# MCU_FSS0_OSPI_0_OSPI0_SS_CFG register map
Vendor: Texas Instruments
Peripheral module from a debugger description file (folder J7_AHP).
Registers are 32-bit, read-only, reset 0x0 unless marked. A register's access mark holds for its fields unless they carry their own. Offsets are as the file gives them; lines under a group give offsets from that group; [hi:lo] are bit positions; {n}, {i} and the like mark numbered series; 'fields as' and 'values as' point back to an identical list; <NAME> marks a mode.

## MCU_FSS0_OSPI_0_OSPI0_SS_CFG
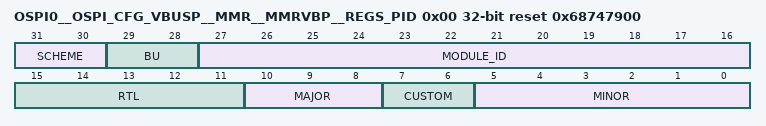
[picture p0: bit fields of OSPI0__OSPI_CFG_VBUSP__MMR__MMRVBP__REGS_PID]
0x00 OSPI0__OSPI_CFG_VBUSP__MMR__MMRVBP__REGS_PID reset 0x68747900
  [31:30] SCHEME — PID register scheme
  [29:28] BU — Business Unit: 10 = Processors
  [27:16] MODULE_ID
  [15:11] RTL — RTL revision. Will vary depending on release.
  [10:8] MAJOR — Major revision
  [7:6] CUSTOM
  [5:0] MINOR — Minor revision
0x04 OSPI0__OSPI_CFG_VBUSP__MMR__MMRVBP__REGS_CTRL rw
  [3] PIPELINE_MODE_FLUSH — 1 - Flush Cadence Flash Controller FIFO by forcin gAHB SEL low. 0 - AHB Sel to Cadence Controller is 1
0x08 OSPI0__OSPI_CFG_VBUSP__MMR__MMRVBP__REGS_STAT
  [1] MEM_INIT_DONE — 0:Memory Initialization is in progress, 1:Memory Intialization Done
0x20 OSPI0__OSPI_CFG_VBUSP__MMR__MMRVBP__REGS_EOI wo
  [7:0] EOI — Write with bit position of targetted interrupt. (E.g. Ext TS is bit 0). Upon write, level interrupt will clear and if unserviced interrupt counter > 1 will issue another pulse interrupt
